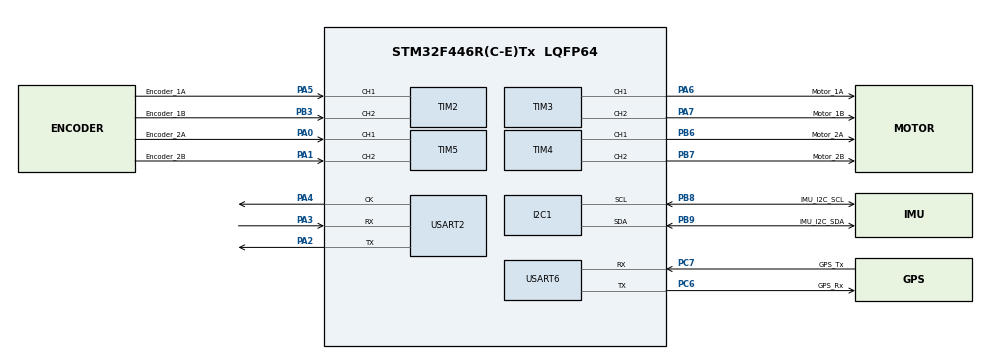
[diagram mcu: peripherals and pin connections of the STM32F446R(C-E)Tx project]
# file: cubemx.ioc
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Mcu.Family=STM32F4
Mcu.Name=STM32F446R(C-E)Tx
Mcu.Package=LQFP64
NVIC.PriorityGroup=NVIC_PRIORITYGROUP_4
PA0-WKUP.GPIO_Label=Encoder_2A
PA0-WKUP.Signal=S_TIM5_CH1
PA1.GPIO_Label=Encoder_2B
PA1.Signal=S_TIM5_CH2
PA2.Mode=Synchronous
PA2.Signal=USART2_TX
PA3.Mode=Synchronous
PA3.Signal=USART2_RX
PA4.Mode=Synchronous
PA4.Signal=USART2_CK
PA5.GPIO_Label=Encoder_1A
PA5.Signal=S_TIM2_CH1_ETR
PA6.GPIO_Label=Motor_1A
PA6.Signal=S_TIM3_CH1
PA7.GPIO_Label=Motor_1B
PA7.Signal=S_TIM3_CH2
PB3.GPIO_Label=Encoder_1B
PB3.Signal=S_TIM2_CH2
PB6.GPIO_Label=Motor_2A
PB6.Signal=S_TIM4_CH1
PB7.GPIO_Label=Motor_2B
PB7.Signal=S_TIM4_CH2
PB8.GPIO_Label=IMU_I2C_SCL
PB8.Mode=I2C
PB8.Signal=I2C1_SCL
PB9.GPIO_Label=IMU_I2C_SDA
PB9.Mode=I2C
PB9.Signal=I2C1_SDA
PC6.GPIO_Label=GPS_Rx
PC6.Mode=Asynchronous
PC6.Signal=USART6_TX
PC7.GPIO_Label=GPS_Tx
PC7.Mode=Asynchronous
PC7.Signal=USART6_RX
ProjectManager.HeapSize=0x200
ProjectManager.StackSize=0x400
ProjectManager.TargetToolchain=STM32CubeIDE
RCC.CortexFreq_Value=16000000
RCC.USBFreq_Value=96000000
RCC.VCOOutputFreq_Value=192000000
SH.S_TIM2_CH1_ETR.0=TIM2_CH1,Encoder_Interface
SH.S_TIM2_CH2.0=TIM2_CH2,Encoder_Interface
SH.S_TIM3_CH1.0=TIM3_CH1,PWM Generation1 CH1
SH.S_TIM3_CH2.0=TIM3_CH2,PWM Generation2 CH2
SH.S_TIM4_CH1.0=TIM4_CH1,PWM Generation1 CH1
SH.S_TIM4_CH2.0=TIM4_CH2,PWM Generation2 CH2
SH.S_TIM5_CH1.0=TIM5_CH1,Encoder_Interface
SH.S_TIM5_CH2.0=TIM5_CH2,Encoder_Interface
TIM3.Channel-PWM\ Generation1\ CH1=TIM_CHANNEL_1
TIM3.Channel-PWM\ Generation2\ CH2=TIM_CHANNEL_2
TIM4.Channel-PWM\ Generation1\ CH1=TIM_CHANNEL_1
TIM4.Channel-PWM\ Generation2\ CH2=TIM_CHANNEL_2
TIM5.EncoderMode=TIM_ENCODERMODE_TI12
USART2.VirtualMode=VM_SYNC
USART6.VirtualMode=VM_ASYNC
board=custom

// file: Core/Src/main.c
/* USER CODE BEGIN Header */
/**
  ******************************************************************************
  * @file           : main.c
  * @brief          : Main program body
  ******************************************************************************
  * @attention
  *
  * Copyright (c) 2023 STMicroelectronics.
  * All rights reserved.
  *
  * This software is licensed under terms that can be found in the LICENSE file
  * in the root directory of this software component.
  * If no LICENSE file comes with this software, it is provided AS-IS.
  *
  ******************************************************************************
  */
/* USER CODE END Header */
#include "main.h"

I2C_HandleTypeDef hi2c1;

TIM_HandleTypeDef htim2;
TIM_HandleTypeDef htim3;
TIM_HandleTypeDef htim4;
TIM_HandleTypeDef htim5;

USART_HandleTypeDef husart2;
UART_HandleTypeDef huart6;

void SystemClock_Config(void);
static void MX_GPIO_Init(void);
static void MX_I2C1_Init(void);
static void MX_TIM2_Init(void);
static void MX_TIM3_Init(void);
static void MX_TIM4_Init(void);
static void MX_TIM5_Init(void);
static void MX_USART6_UART_Init(void);
static void MX_USART2_Init(void);

int main(void)
{

  /* MCU Configuration--------------------------------------------------------*/

  /* Reset of all peripherals, Initializes the Flash interface and the Systick. */
  HAL_Init();

  /* Configure the system clock */
  SystemClock_Config();

  /* Initialize all configured peripherals */
  MX_GPIO_Init();
  MX_I2C1_Init();
  MX_TIM2_Init();
  MX_TIM3_Init();
  MX_TIM4_Init();
  MX_TIM5_Init();
  MX_USART6_UART_Init();
  MX_USART2_Init();

  /* Infinite loop */
  /* USER CODE BEGIN WHILE */
  while (1)
  {
	  UART
    /* USER CODE END WHILE */
	  uint32_t encCnt = TIM5->CNT;
	  uint8_t datau8[16] = {0x68,0x65,0x6C,0x6C,0x6F,0x77,0x20,0x77,0x6F,0x72,0x6C,0x64,0x5C,0x6E,0x5C,0x72};
	  HAL_USART_Transmit(&husart2, datau8, 16, 1000);
	  HAL_Delay(1000);
  }
}

void SystemClock_Config(void)
{
  RCC_OscInitTypeDef RCC_OscInitStruct = {0};
  RCC_ClkInitTypeDef RCC_ClkInitStruct = {0};

  /** Configure the main internal regulator output voltage
  */
  __HAL_RCC_PWR_CLK_ENABLE();
  __HAL_PWR_VOLTAGESCALING_CONFIG(PWR_REGULATOR_VOLTAGE_SCALE3);

  /** Initializes the RCC Oscillators according to the specified parameters
  * in the RCC_OscInitTypeDef structure.
  */
  RCC_OscInitStruct.OscillatorType = RCC_OSCILLATORTYPE_HSI;
  RCC_OscInitStruct.HSIState = RCC_HSI_ON;
  RCC_OscInitStruct.HSICalibrationValue = RCC_HSICALIBRATION_DEFAULT;
  RCC_OscInitStruct.PLL.PLLState = RCC_PLL_NONE;
  if (HAL_RCC_OscConfig(&RCC_OscInitStruct) != HAL_OK)
  {
    Error_Handler();
  }

  /** Initializes the CPU, AHB and APB buses clocks
  */
  RCC_ClkInitStruct.ClockType = RCC_CLOCKTYPE_HCLK|RCC_CLOCKTYPE_SYSCLK
                              |RCC_CLOCKTYPE_PCLK1|RCC_CLOCKTYPE_PCLK2;
  RCC_ClkInitStruct.SYSCLKSource = RCC_SYSCLKSOURCE_HSI;
  RCC_ClkInitStruct.AHBCLKDivider = RCC_SYSCLK_DIV1;
  RCC_ClkInitStruct.APB1CLKDivider = RCC_HCLK_DIV1;
  RCC_ClkInitStruct.APB2CLKDivider = RCC_HCLK_DIV1;

  if (HAL_RCC_ClockConfig(&RCC_ClkInitStruct, FLASH_LATENCY_0) != HAL_OK)
  {
    Error_Handler();
  }
}

static void MX_I2C1_Init(void)
{

  hi2c1.Instance = I2C1;
  hi2c1.Init.ClockSpeed = 100000;
  hi2c1.Init.DutyCycle = I2C_DUTYCYCLE_2;
  hi2c1.Init.OwnAddress1 = 0;
  hi2c1.Init.AddressingMode = I2C_ADDRESSINGMODE_7BIT;
  hi2c1.Init.DualAddressMode = I2C_DUALADDRESS_DISABLE;
  hi2c1.Init.OwnAddress2 = 0;
  hi2c1.Init.GeneralCallMode = I2C_GENERALCALL_DISABLE;
  hi2c1.Init.NoStretchMode = I2C_NOSTRETCH_DISABLE;
  if (HAL_I2C_Init(&hi2c1) != HAL_OK)
  {
    Error_Handler();
  }

}

static void MX_TIM2_Init(void)
{

  TIM_Encoder_InitTypeDef sConfig = {0};
  TIM_MasterConfigTypeDef sMasterConfig = {0};

  htim2.Instance = TIM2;
  htim2.Init.Prescaler = 0;
  htim2.Init.CounterMode = TIM_COUNTERMODE_UP;
  htim2.Init.Period = 4294967295;
  htim2.Init.ClockDivision = TIM_CLOCKDIVISION_DIV1;
  htim2.Init.AutoReloadPreload = TIM_AUTORELOAD_PRELOAD_DISABLE;
  sConfig.EncoderMode = TIM_ENCODERMODE_TI1;
  sConfig.IC1Polarity = TIM_ICPOLARITY_RISING;
  sConfig.IC1Selection = TIM_ICSELECTION_DIRECTTI;
  sConfig.IC1Prescaler = TIM_ICPSC_DIV1;
  sConfig.IC1Filter = 0;
  sConfig.IC2Polarity = TIM_ICPOLARITY_RISING;
  sConfig.IC2Selection = TIM_ICSELECTION_DIRECTTI;
  sConfig.IC2Prescaler = TIM_ICPSC_DIV1;
  sConfig.IC2Filter = 0;
  if (HAL_TIM_Encoder_Init(&htim2, &sConfig) != HAL_OK)
  {
    Error_Handler();
  }
  sMasterConfig.MasterOutputTrigger = TIM_TRGO_RESET;
  sMasterConfig.MasterSlaveMode = TIM_MASTERSLAVEMODE_DISABLE;
  if (HAL_TIMEx_MasterConfigSynchronization(&htim2, &sMasterConfig) != HAL_OK)
  {
    Error_Handler();
  }

}

static void MX_TIM3_Init(void)
{

  TIM_MasterConfigTypeDef sMasterConfig = {0};
  TIM_OC_InitTypeDef sConfigOC = {0};

  htim3.Instance = TIM3;
  htim3.Init.Prescaler = 0;
  htim3.Init.CounterMode = TIM_COUNTERMODE_UP;
  htim3.Init.Period = 65535;
  htim3.Init.ClockDivision = TIM_CLOCKDIVISION_DIV1;
  htim3.Init.AutoReloadPreload = TIM_AUTORELOAD_PRELOAD_DISABLE;
  if (HAL_TIM_PWM_Init(&htim3) != HAL_OK)
  {
    Error_Handler();
  }
  sMasterConfig.MasterOutputTrigger = TIM_TRGO_RESET;
  sMasterConfig.MasterSlaveMode = TIM_MASTERSLAVEMODE_DISABLE;
  if (HAL_TIMEx_MasterConfigSynchronization(&htim3, &sMasterConfig) != HAL_OK)
  {
    Error_Handler();
  }
  sConfigOC.OCMode = TIM_OCMODE_PWM1;
  sConfigOC.Pulse = 0;
  sConfigOC.OCPolarity = TIM_OCPOLARITY_HIGH;
  sConfigOC.OCFastMode = TIM_OCFAST_DISABLE;
  if (HAL_TIM_PWM_ConfigChannel(&htim3, &sConfigOC, TIM_CHANNEL_1) != HAL_OK)
  {
    Error_Handler();
  }
  if (HAL_TIM_PWM_ConfigChannel(&htim3, &sConfigOC, TIM_CHANNEL_2) != HAL_OK)
  {
    Error_Handler();
  }
  HAL_TIM_MspPostInit(&htim3);

}

static void MX_TIM4_Init(void)
{

  TIM_MasterConfigTypeDef sMasterConfig = {0};
  TIM_OC_InitTypeDef sConfigOC = {0};

  htim4.Instance = TIM4;
  htim4.Init.Prescaler = 0;
  htim4.Init.CounterMode = TIM_COUNTERMODE_UP;
  htim4.Init.Period = 65535;
  htim4.Init.ClockDivision = TIM_CLOCKDIVISION_DIV1;
  htim4.Init.AutoReloadPreload = TIM_AUTORELOAD_PRELOAD_DISABLE;
  if (HAL_TIM_PWM_Init(&htim4) != HAL_OK)
  {
    Error_Handler();
  }
  sMasterConfig.MasterOutputTrigger = TIM_TRGO_RESET;
  sMasterConfig.MasterSlaveMode = TIM_MASTERSLAVEMODE_DISABLE;
  if (HAL_TIMEx_MasterConfigSynchronization(&htim4, &sMasterConfig) != HAL_OK)
  {
    Error_Handler();
  }
  sConfigOC.OCMode = TIM_OCMODE_PWM1;
  sConfigOC.Pulse = 0;
  sConfigOC.OCPolarity = TIM_OCPOLARITY_HIGH;
  sConfigOC.OCFastMode = TIM_OCFAST_DISABLE;
  if (HAL_TIM_PWM_ConfigChannel(&htim4, &sConfigOC, TIM_CHANNEL_1) != HAL_OK)
  {
    Error_Handler();
  }
  if (HAL_TIM_PWM_ConfigChannel(&htim4, &sConfigOC, TIM_CHANNEL_2) != HAL_OK)
  {
    Error_Handler();
  }
  HAL_TIM_MspPostInit(&htim4);

}

static void MX_TIM5_Init(void)
{

  TIM_Encoder_InitTypeDef sConfig = {0};
  TIM_MasterConfigTypeDef sMasterConfig = {0};

  htim5.Instance = TIM5;
  htim5.Init.Prescaler = 0;
  htim5.Init.CounterMode = TIM_COUNTERMODE_UP;
  htim5.Init.Period = 4294967295;
  htim5.Init.ClockDivision = TIM_CLOCKDIVISION_DIV1;
  htim5.Init.AutoReloadPreload = TIM_AUTORELOAD_PRELOAD_DISABLE;
  sConfig.EncoderMode = TIM_ENCODERMODE_TI12;
  sConfig.IC1Polarity = TIM_ICPOLARITY_RISING;
  sConfig.IC1Selection = TIM_ICSELECTION_DIRECTTI;
  sConfig.IC1Prescaler = TIM_ICPSC_DIV1;
  sConfig.IC1Filter = 0;
  sConfig.IC2Polarity = TIM_ICPOLARITY_RISING;
  sConfig.IC2Selection = TIM_ICSELECTION_DIRECTTI;
  sConfig.IC2Prescaler = TIM_ICPSC_DIV1;
  sConfig.IC2Filter = 0;
  if (HAL_TIM_Encoder_Init(&htim5, &sConfig) != HAL_OK)
  {
    Error_Handler();
  }
  sMasterConfig.MasterOutputTrigger = TIM_TRGO_RESET;
  sMasterConfig.MasterSlaveMode = TIM_MASTERSLAVEMODE_DISABLE;
  if (HAL_TIMEx_MasterConfigSynchronization(&htim5, &sMasterConfig) != HAL_OK)
  {
    Error_Handler();
  }

}

static void MX_USART2_Init(void)
{

  husart2.Instance = USART2;
  husart2.Init.BaudRate = 115200;
  husart2.Init.WordLength = USART_WORDLENGTH_8B;
  husart2.Init.StopBits = USART_STOPBITS_1;
  husart2.Init.Parity = USART_PARITY_NONE;
  husart2.Init.Mode = USART_MODE_TX_RX;
  husart2.Init.CLKPolarity = USART_POLARITY_LOW;
  husart2.Init.CLKPhase = USART_PHASE_1EDGE;
  husart2.Init.CLKLastBit = USART_LASTBIT_DISABLE;
  if (HAL_USART_Init(&husart2) != HAL_OK)
  {
    Error_Handler();
  }

}

static void MX_USART6_UART_Init(void)
{

  huart6.Instance = USART6;
  huart6.Init.BaudRate = 115200;
  huart6.Init.WordLength = UART_WORDLENGTH_8B;
  huart6.Init.StopBits = UART_STOPBITS_1;
  huart6.Init.Parity = UART_PARITY_NONE;
  huart6.Init.Mode = UART_MODE_TX_RX;
  huart6.Init.HwFlowCtl = UART_HWCONTROL_NONE;
  huart6.Init.OverSampling = UART_OVERSAMPLING_16;
  if (HAL_UART_Init(&huart6) != HAL_OK)
  {
    Error_Handler();
  }

}

static void MX_GPIO_Init(void)
{

  /* GPIO Ports Clock Enable */
  __HAL_RCC_GPIOA_CLK_ENABLE();
  __HAL_RCC_GPIOC_CLK_ENABLE();
  __HAL_RCC_GPIOB_CLK_ENABLE();

}

void Error_Handler(void)
{
  __disable_irq();
  while (1)
  {
  }
}
